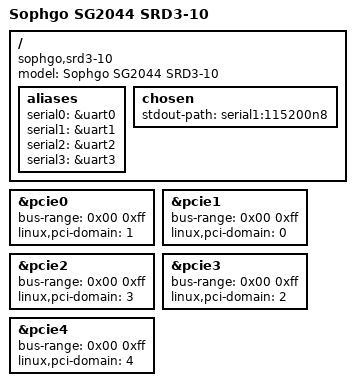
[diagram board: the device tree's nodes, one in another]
// SPDX-License-Identifier: (GPL-2.0 OR MIT)
/*
 * Copyright (C) 2025 Inochi Amaoto <inochiama@gmail.com>
 */

/dts-v1/;

#include "sg2044-sophgo-srd3-10-common.dtsi"
#include "sg2044-pcie-legacy-layout.dtsi"

/ {
	model = "Sophgo SG2044 SRD3-10";
	compatible = "sophgo,srd3-10", "sophgo,sg2044";

	aliases {
		serial0 = &uart0;
		serial1 = &uart1;
		serial2 = &uart2;
		serial3 = &uart3;
	};

	chosen {
		stdout-path = "serial1:115200n8";
	};
};

&pcie0 {
	bus-range = <0x00 0xff>;
	linux,pci-domain = <1>;
	status = "okay";
};

&pcie1 {
	bus-range = <0x00 0xff>;
	linux,pci-domain = <0>;
	status = "okay";
};

&pcie2 {
	bus-range = <0x00 0xff>;
	linux,pci-domain = <3>;
	status = "okay";
};

&pcie3 {
	bus-range = <0x00 0xff>;
	linux,pci-domain = <2>;
	status = "okay";
};

&pcie4 {
	bus-range = <0x00 0xff>;
	linux,pci-domain = <4>;
	status = "okay";
};
